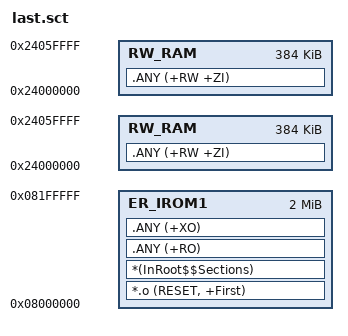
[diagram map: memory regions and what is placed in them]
LR_IROM1 0x08000000 0x00200000  {    ; load region size_region
  ER_IROM1 0x08000000 0x00200000  {  ; load address = execution address
   *.o (RESET, +First)
   *(InRoot$$Sections)
   .ANY (+RO)
   .ANY (+XO)
  }
  RW_RAM 0x24000000 0x00060000 {
   .ANY (+RW +ZI)
  }
  RW_RAM 0x24000000 0x00060000 {
   .ANY (+RW +ZI)
  }
}

